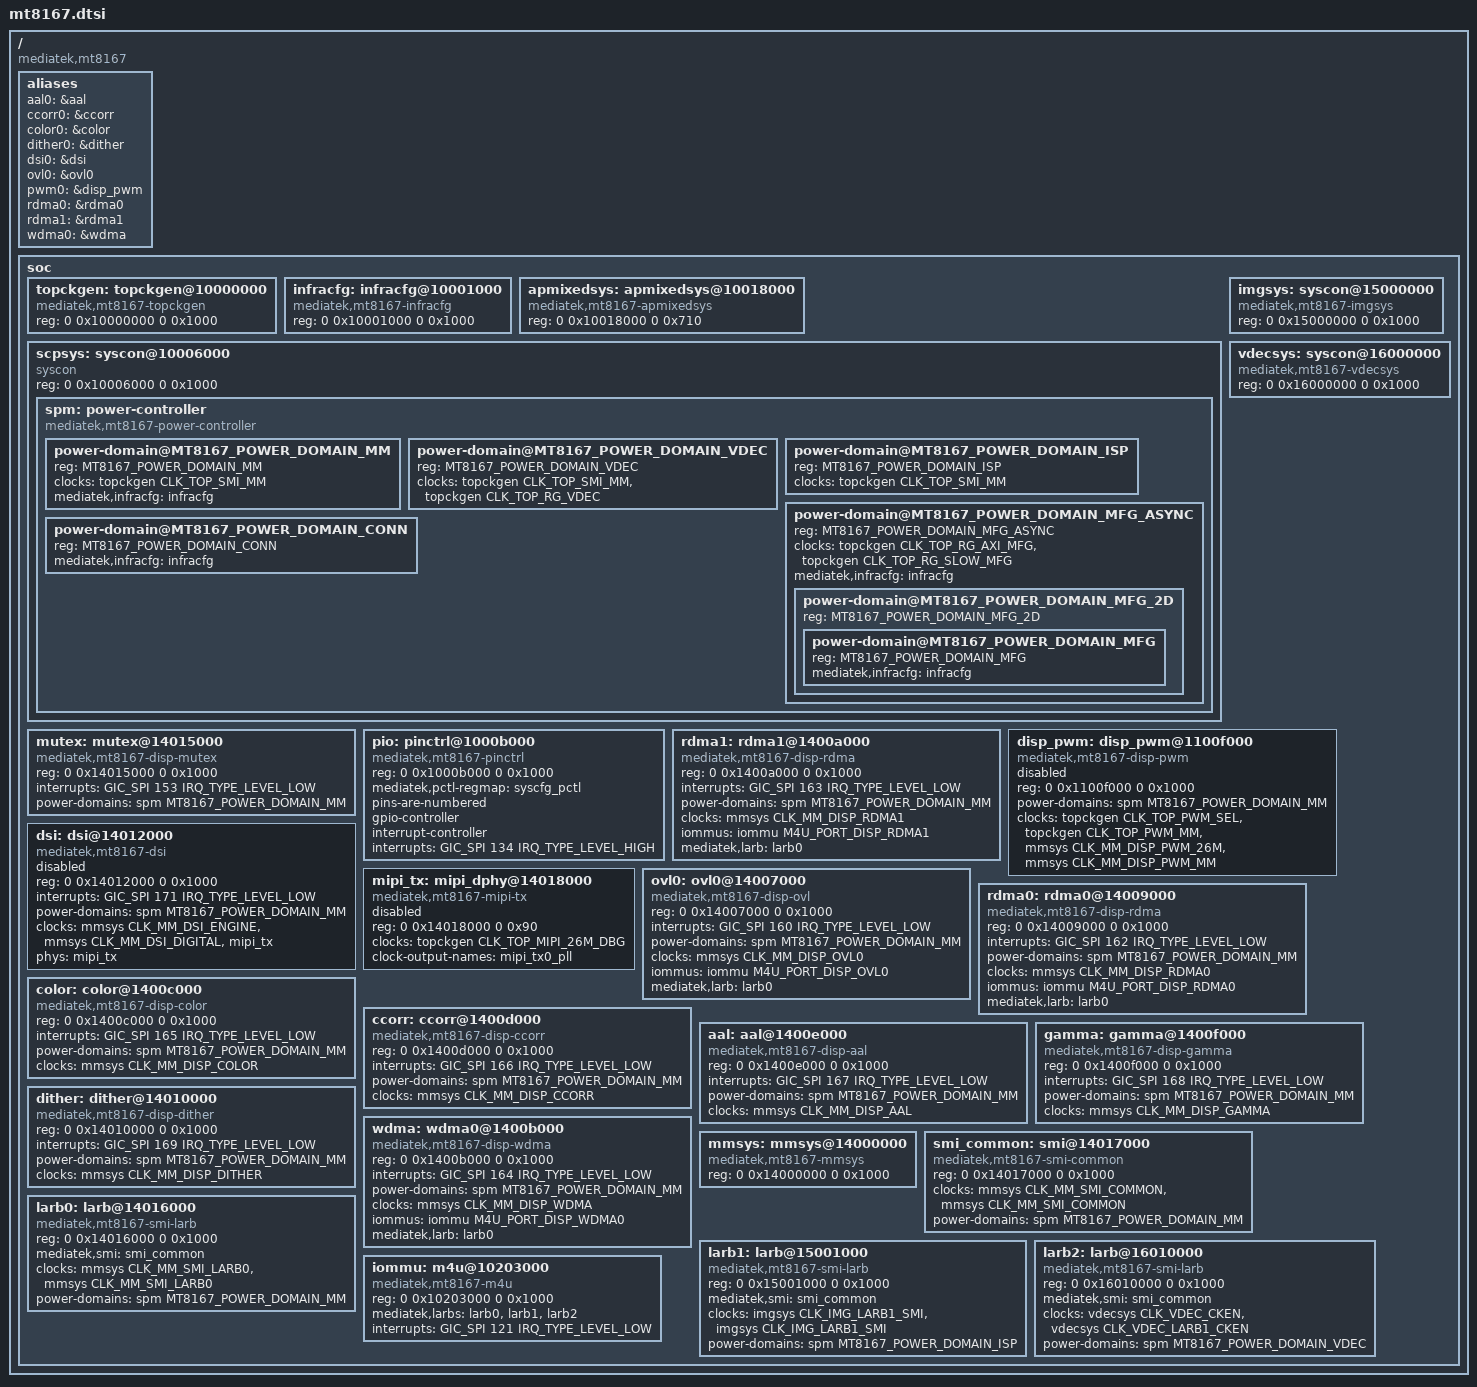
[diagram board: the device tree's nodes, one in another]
// SPDX-License-Identifier: GPL-2.0
/*
 * Copyright (c) 2020 MediaTek Inc.
 * Copyright (c) 2020 BayLibre, SAS.
 * Author: Fabien Parent <fparent@baylibre.com>
 */

#include <dt-bindings/clock/mt8167-clk.h>
#include <dt-bindings/memory/mt8167-larb-port.h>
#include <dt-bindings/power/mt8167-power.h>

#include "mt8167-pinfunc.h"

#include "mt8516.dtsi"

/ {
	compatible = "mediatek,mt8167";

	aliases {
		aal0 = &aal;
		ccorr0 = &ccorr;
		color0 = &color;
		dither0 = &dither;
		dsi0 = &dsi;
		ovl0 = &ovl0;
		pwm0 = &disp_pwm;
		rdma0 = &rdma0;
		rdma1 = &rdma1;
		wdma0 = &wdma;
	};

	soc {
		topckgen: topckgen@10000000 {
			compatible = "mediatek,mt8167-topckgen", "syscon";
			reg = <0 0x10000000 0 0x1000>;
			#clock-cells = <1>;
		};

		infracfg: infracfg@10001000 {
			compatible = "mediatek,mt8167-infracfg", "syscon";
			reg = <0 0x10001000 0 0x1000>;
			#clock-cells = <1>;
		};

		apmixedsys: apmixedsys@10018000 {
			compatible = "mediatek,mt8167-apmixedsys", "syscon";
			reg = <0 0x10018000 0 0x710>;
			#clock-cells = <1>;
		};

		scpsys: syscon@10006000 {
			compatible = "syscon", "simple-mfd";
			reg = <0 0x10006000 0 0x1000>;
			#power-domain-cells = <1>;

			spm: power-controller {
				compatible = "mediatek,mt8167-power-controller";
				#address-cells = <1>;
				#size-cells = <0>;
				#power-domain-cells = <1>;

				/* power domains of the SoC */
				power-domain@MT8167_POWER_DOMAIN_MM {
					reg = <MT8167_POWER_DOMAIN_MM>;
					clocks = <&topckgen CLK_TOP_SMI_MM>;
					clock-names = "mm";
					#power-domain-cells = <0>;
					mediatek,infracfg = <&infracfg>;
				};

				power-domain@MT8167_POWER_DOMAIN_VDEC {
					reg = <MT8167_POWER_DOMAIN_VDEC>;
					clocks = <&topckgen CLK_TOP_SMI_MM>,
						 <&topckgen CLK_TOP_RG_VDEC>;
					clock-names = "mm", "vdec";
					#power-domain-cells = <0>;
				};

				power-domain@MT8167_POWER_DOMAIN_ISP {
					reg = <MT8167_POWER_DOMAIN_ISP>;
					clocks = <&topckgen CLK_TOP_SMI_MM>;
					clock-names = "mm";
					#power-domain-cells = <0>;
				};

				power-domain@MT8167_POWER_DOMAIN_MFG_ASYNC {
					reg = <MT8167_POWER_DOMAIN_MFG_ASYNC>;
					clocks = <&topckgen CLK_TOP_RG_AXI_MFG>,
						 <&topckgen CLK_TOP_RG_SLOW_MFG>;
					clock-names = "axi_mfg", "mfg";
					#address-cells = <1>;
					#size-cells = <0>;
					#power-domain-cells = <1>;
					mediatek,infracfg = <&infracfg>;

					power-domain@MT8167_POWER_DOMAIN_MFG_2D {
						reg = <MT8167_POWER_DOMAIN_MFG_2D>;
						#address-cells = <1>;
						#size-cells = <0>;
						#power-domain-cells = <1>;

						power-domain@MT8167_POWER_DOMAIN_MFG {
							reg = <MT8167_POWER_DOMAIN_MFG>;
							#power-domain-cells = <0>;
							mediatek,infracfg = <&infracfg>;
						};
					};
				};

				power-domain@MT8167_POWER_DOMAIN_CONN {
					reg = <MT8167_POWER_DOMAIN_CONN>;
					#power-domain-cells = <0>;
					mediatek,infracfg = <&infracfg>;
				};
			};
		};

		imgsys: syscon@15000000 {
			compatible = "mediatek,mt8167-imgsys", "syscon";
			reg = <0 0x15000000 0 0x1000>;
			#clock-cells = <1>;
		};

		vdecsys: syscon@16000000 {
			compatible = "mediatek,mt8167-vdecsys", "syscon";
			reg = <0 0x16000000 0 0x1000>;
			#clock-cells = <1>;
		};

		mutex: mutex@14015000 {
			compatible = "mediatek,mt8167-disp-mutex";
			reg = <0 0x14015000 0 0x1000>;
			interrupts = <GIC_SPI 153 IRQ_TYPE_LEVEL_LOW>;
			power-domains = <&spm MT8167_POWER_DOMAIN_MM>;
		};

		pio: pinctrl@1000b000 {
			compatible = "mediatek,mt8167-pinctrl";
			reg = <0 0x1000b000 0 0x1000>;
			mediatek,pctl-regmap = <&syscfg_pctl>;
			pins-are-numbered;
			gpio-controller;
			#gpio-cells = <2>;
			interrupt-controller;
			#interrupt-cells = <2>;
			interrupts = <GIC_SPI 134 IRQ_TYPE_LEVEL_HIGH>;
		};

		rdma1: rdma1@1400a000 {
			compatible = "mediatek,mt8167-disp-rdma",
				     "mediatek,mt2701-disp-rdma";
			reg = <0 0x1400a000 0 0x1000>;
			interrupts = <GIC_SPI 163 IRQ_TYPE_LEVEL_LOW>;
			power-domains = <&spm MT8167_POWER_DOMAIN_MM>;
			clocks = <&mmsys CLK_MM_DISP_RDMA1>;
			iommus = <&iommu M4U_PORT_DISP_RDMA1>;
			mediatek,larb = <&larb0>;
		};

		disp_pwm: disp_pwm@1100f000 {
			compatible = "mediatek,mt8167-disp-pwm",
				     "mediatek,mt8173-disp-pwn";
			reg = <0 0x1100f000 0 0x1000>;
			#pwm-cells = <2>;
			power-domains = <&spm MT8167_POWER_DOMAIN_MM>;
			clocks = <&topckgen CLK_TOP_PWM_SEL>,
				 <&topckgen CLK_TOP_PWM_MM>,
				  <&mmsys CLK_MM_DISP_PWM_26M>,
				  <&mmsys CLK_MM_DISP_PWM_MM>;
			clock-names = "pwm_sel",
				      "pwm_mm",
				      "main",
				      "mm";
			status = "disabled";
		};

		dsi: dsi@14012000 {
			compatible = "mediatek,mt8167-dsi",
				     "mediatek,mt2701-dsi";
			reg = <0 0x14012000 0 0x1000>;
			interrupts = <GIC_SPI 171 IRQ_TYPE_LEVEL_LOW>;
			power-domains = <&spm MT8167_POWER_DOMAIN_MM>;
			clocks = <&mmsys CLK_MM_DSI_ENGINE>,
				 <&mmsys CLK_MM_DSI_DIGITAL>,
				 <&mipi_tx>;
			clock-names = "engine", "digital", "hs";
			phys = <&mipi_tx>;
			phy-names = "dphy";
			status = "disabled";
		};

		mipi_tx: mipi_dphy@14018000 {
			compatible = "mediatek,mt8167-mipi-tx",
				     "mediatek,mt2701-mipi-tx";
			reg = <0 0x14018000 0 0x90>;
			clocks = <&topckgen CLK_TOP_MIPI_26M_DBG>;
			clock-output-names = "mipi_tx0_pll";
			#clock-cells = <0>;
			#phy-cells = <0>;
			status = "disabled";
		};

		ovl0: ovl0@14007000 {
			compatible = "mediatek,mt8167-disp-ovl",
				     "mediatek,mt8173-disp-ovl";
			reg = <0 0x14007000 0 0x1000>;
			interrupts = <GIC_SPI 160 IRQ_TYPE_LEVEL_LOW>;
			power-domains = <&spm MT8167_POWER_DOMAIN_MM>;
			clocks = <&mmsys CLK_MM_DISP_OVL0>;
			iommus = <&iommu M4U_PORT_DISP_OVL0>;
			mediatek,larb = <&larb0>;
		};

		rdma0: rdma0@14009000 {
			compatible = "mediatek,mt8167-disp-rdma",
				     "mediatek,mt2701-disp-rdma";
			reg = <0 0x14009000 0 0x1000>;
			interrupts = <GIC_SPI 162 IRQ_TYPE_LEVEL_LOW>;
			power-domains = <&spm MT8167_POWER_DOMAIN_MM>;
			clocks = <&mmsys CLK_MM_DISP_RDMA0>;
			iommus = <&iommu M4U_PORT_DISP_RDMA0>;
			mediatek,larb = <&larb0>;
		};

		color: color@1400c000 {
			compatible = "mediatek,mt8167-disp-color",
				     "mediatek,mt8173-disp-color";
			reg = <0 0x1400c000 0 0x1000>;
			interrupts = <GIC_SPI 165 IRQ_TYPE_LEVEL_LOW>;
			power-domains = <&spm MT8167_POWER_DOMAIN_MM>;
			clocks = <&mmsys CLK_MM_DISP_COLOR>;
		};

		ccorr: ccorr@1400d000 {
			compatible = "mediatek,mt8167-disp-ccorr",
				     "mediatek,mt8183-disp-ccorr";
			reg = <0 0x1400d000 0 0x1000>;
			interrupts = <GIC_SPI 166 IRQ_TYPE_LEVEL_LOW>;
			power-domains = <&spm MT8167_POWER_DOMAIN_MM>;
			clocks = <&mmsys CLK_MM_DISP_CCORR>;
		};

		aal: aal@1400e000 {
			compatible = "mediatek,mt8167-disp-aal";
			reg = <0 0x1400e000 0 0x1000>;
			interrupts = <GIC_SPI 167 IRQ_TYPE_LEVEL_LOW>;
			power-domains = <&spm MT8167_POWER_DOMAIN_MM>;
			clocks = <&mmsys CLK_MM_DISP_AAL>;
		};

		gamma: gamma@1400f000 {
			compatible = "mediatek,mt8167-disp-gamma",
				     "mediatek,mt8173-disp-gamma";
			reg = <0 0x1400f000 0 0x1000>;
			interrupts = <GIC_SPI 168 IRQ_TYPE_LEVEL_LOW>;
			power-domains = <&spm MT8167_POWER_DOMAIN_MM>;
			clocks = <&mmsys CLK_MM_DISP_GAMMA>;
		};

		dither: dither@14010000 {
			compatible = "mediatek,mt8167-disp-dither";
			reg = <0 0x14010000 0 0x1000>;
			interrupts = <GIC_SPI 169 IRQ_TYPE_LEVEL_LOW>;
			power-domains = <&spm MT8167_POWER_DOMAIN_MM>;
			clocks = <&mmsys CLK_MM_DISP_DITHER>;
		};

		wdma: wdma0@1400b000 {
			compatible = "mediatek,mt8167-disp-wdma";
			reg = <0 0x1400b000 0 0x1000>;
			interrupts = <GIC_SPI 164 IRQ_TYPE_LEVEL_LOW>;
			power-domains = <&spm MT8167_POWER_DOMAIN_MM>;
			clocks = <&mmsys CLK_MM_DISP_WDMA>;
			iommus = <&iommu M4U_PORT_DISP_WDMA0>;
			mediatek,larb = <&larb0>;
		};

		mmsys: mmsys@14000000 {
			compatible = "mediatek,mt8167-mmsys", "syscon";
			reg = <0 0x14000000 0 0x1000>;
			#clock-cells = <1>;
		};

		smi_common: smi@14017000 {
			compatible = "mediatek,mt8167-smi-common";
			reg = <0 0x14017000 0 0x1000>;
			clocks = <&mmsys CLK_MM_SMI_COMMON>,
				 <&mmsys CLK_MM_SMI_COMMON>;
			clock-names = "apb", "smi";
			power-domains = <&spm MT8167_POWER_DOMAIN_MM>;
		};

		larb0: larb@14016000 {
			compatible = "mediatek,mt8167-smi-larb";
			reg = <0 0x14016000 0 0x1000>;
			mediatek,smi = <&smi_common>;
			clocks = <&mmsys CLK_MM_SMI_LARB0>,
				 <&mmsys CLK_MM_SMI_LARB0>;
			clock-names = "apb", "smi";
			power-domains = <&spm MT8167_POWER_DOMAIN_MM>;
		};

		larb1: larb@15001000 {
			compatible = "mediatek,mt8167-smi-larb";
			reg = <0 0x15001000 0 0x1000>;
			mediatek,smi = <&smi_common>;
			clocks = <&imgsys CLK_IMG_LARB1_SMI>,
				 <&imgsys CLK_IMG_LARB1_SMI>;
			clock-names = "apb", "smi";
			power-domains = <&spm MT8167_POWER_DOMAIN_ISP>;
		};

		larb2: larb@16010000 {
			compatible = "mediatek,mt8167-smi-larb";
			reg = <0 0x16010000 0 0x1000>;
			mediatek,smi = <&smi_common>;
			clocks = <&vdecsys CLK_VDEC_CKEN>,
				 <&vdecsys CLK_VDEC_LARB1_CKEN>;
			clock-names = "apb", "smi";
			power-domains = <&spm MT8167_POWER_DOMAIN_VDEC>;
		};

		iommu: m4u@10203000 {
			compatible = "mediatek,mt8167-m4u";
			reg = <0 0x10203000 0 0x1000>;
			mediatek,larbs = <&larb0 &larb1 &larb2>;
			interrupts = <GIC_SPI 121 IRQ_TYPE_LEVEL_LOW>;
			#iommu-cells = <1>;
		};
	};
};
